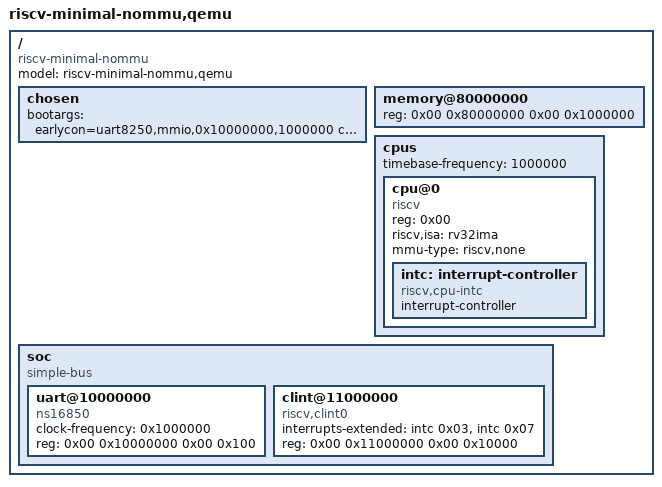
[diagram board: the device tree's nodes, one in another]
/dts-v1/;

/ {
	#address-cells = <0x02>;
	#size-cells = <0x02>;
	compatible = "riscv-minimal-nommu";
	model = "riscv-minimal-nommu,qemu";

	chosen {
		bootargs = "earlycon=uart8250,mmio,0x10000000,1000000 console=ttyS0";
	};

	memory@80000000 {
		device_type = "memory";
		reg = <0x00 0x80000000 0x00 0x1000000>; // 16MB
	};

	cpus {
		#address-cells = <0x01>;
		#size-cells = <0x00>;
		/* sys timer is in Hz */
		timebase-frequency = <1000000>;

		cpu@0 {
			reg = <0x00>;
			device_type = "cpu";
			status = "okay";
			compatible = "riscv";
			riscv,isa = "rv32ima";
			mmu-type = "riscv,none";

			intc: interrupt-controller {
				#interrupt-cells = <0x01>;
				#address-cells = <0x01>;
				interrupt-controller;
				compatible = "riscv,cpu-intc";
				phandle = <0x02>;
			};
		};
	};

	soc {
		#address-cells = <0x02>;
		#size-cells = <0x02>;
		compatible = "simple-bus";
		ranges;

		uart@10000000 {
			clock-frequency = <0x1000000>;
			reg = <0x00 0x10000000 0x00 0x100>;
			compatible = "ns16850";
		};

		clint@11000000 {
			interrupts-extended = <&intc 0x03>,
					      <&intc 0x07>;
			reg = <0x00 0x11000000 0x00 0x10000>;
			compatible = "riscv,clint0";
		};
	};
};
